# HC32F4A8 register map
File version: 1.0
CPU: CM4 r0p1, little endian, MPU, FPU, 4 interrupt priority bits
Registers are 32-bit, read-write, reset 0x0 unless marked. A register's access mark holds for its fields unless they carry their own. Offsets are from the block's base; [hi:lo] are bit positions; {n}, {i} and the like mark numbered series.

## MPU
Base 0x40050000; alternate view of ETH
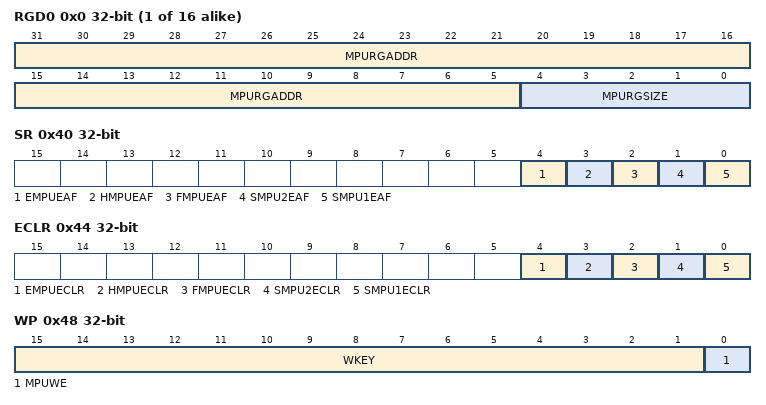
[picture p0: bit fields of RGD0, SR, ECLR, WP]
{0x0+4i} RGD{i} (i=0..15)
  [31:5] MPURGADDR, [4:0] MPURGSIZE
0x40 SR ro
  [4] EMPUEAF, [3] HMPUEAF, [2] FMPUEAF, [1] SMPU2EAF, [0] SMPU1EAF
0x44 ECLR wo
  [4] EMPUECLR, [3] HMPUECLR, [2] FMPUECLR, [1] SMPU2ECLR, [0] SMPU1ECLR
0x48 WP
  [15:1] WKEY, [0] MPUWE
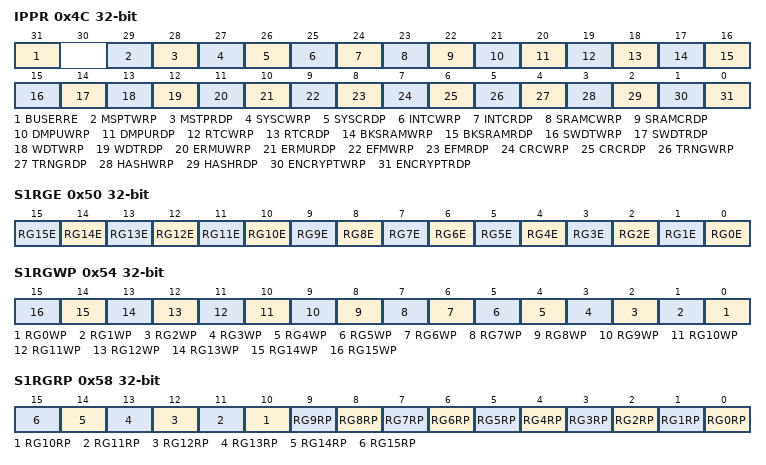
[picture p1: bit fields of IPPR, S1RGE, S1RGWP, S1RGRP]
0x4C IPPR
  [31] BUSERRE, [29] MSPTWRP, [28] MSTPRDP, [27] SYSCWRP, [26] SYSCRDP, [25] INTCWRP, [24] INTCRDP, [23] SRAMCWRP, [22] SRAMCRDP, [21] DMPUWRP, [20] DMPURDP, [19] RTCWRP, [18] RTCRDP, [17] BKSRAMWRP, [16] BKSRAMRDP, [15] SWDTWRP, [14] SWDTRDP, [13] WDTWRP, [12] WDTRDP, [11] ERMUWRP, [10] ERMURDP, [9] EFMWRP, [8] EFMRDP, [7] CRCWRP, [6] CRCRDP, [5] TRNGWRP, [4] TRNGRDP, [3] HASHWRP, [2] HASHRDP, [1] ENCRYPTWRP, [0] ENCRYPTRDP
0x50 S1RGE
  [n] RG{n}E (n=0..15)
0x54 S1RGWP
  [n] RG{n}WP (n=0..15)
0x58 S1RGRP
  [n] RG{n}RP (n=0..15)
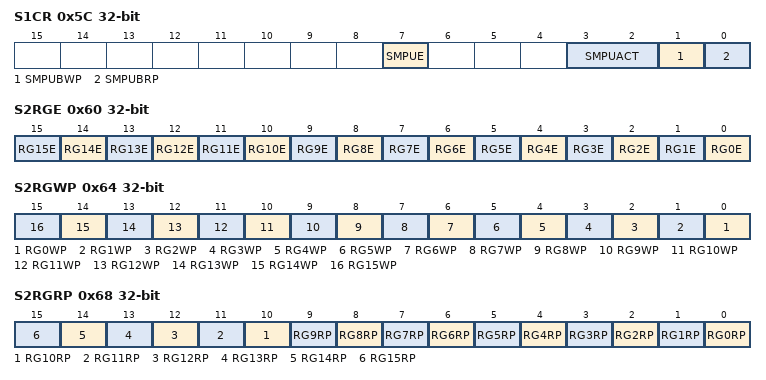
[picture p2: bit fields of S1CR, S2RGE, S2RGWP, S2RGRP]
0x5C S1CR
  [7] SMPUE, [3:2] SMPUACT, [1] SMPUBWP, [0] SMPUBRP
0x60 S2RGE
  [n] RG{n}E (n=0..15)
0x64 S2RGWP
  [n] RG{n}WP (n=0..15)
0x68 S2RGRP
  [n] RG{n}RP (n=0..15)
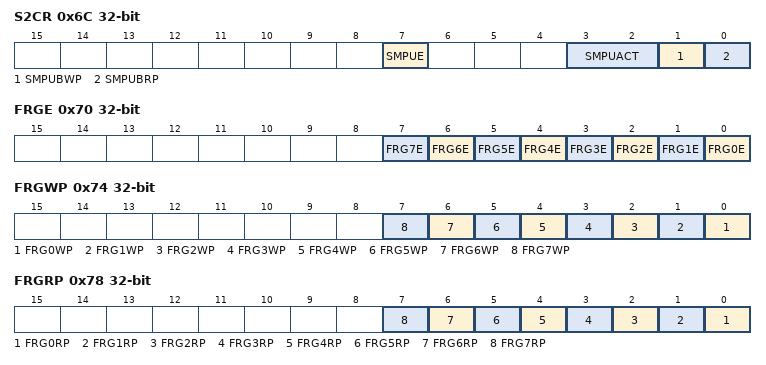
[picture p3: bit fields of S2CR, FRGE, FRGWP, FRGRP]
0x6C S2CR
  [7] SMPUE, [3:2] SMPUACT, [1] SMPUBWP, [0] SMPUBRP
0x70 FRGE
  [n] FRG{n}E (n=0..7)
0x74 FRGWP
  [n] FRG{n}WP (n=0..7)
0x78 FRGRP
  [n] FRG{n}RP (n=0..7)
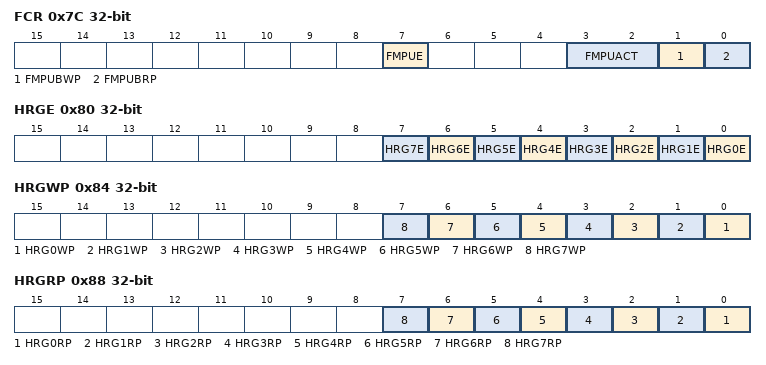
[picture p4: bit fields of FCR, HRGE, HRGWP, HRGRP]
0x7C FCR
  [7] FMPUE, [3:2] FMPUACT, [1] FMPUBWP, [0] FMPUBRP
0x80 HRGE
  [n] HRG{n}E (n=0..7)
0x84 HRGWP
  [n] HRG{n}WP (n=0..7)
0x88 HRGRP
  [n] HRG{n}RP (n=0..7)
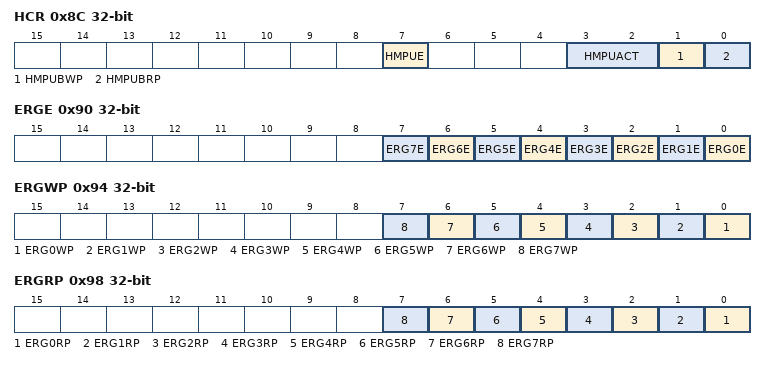
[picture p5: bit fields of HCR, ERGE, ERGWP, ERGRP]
0x8C HCR
  [7] HMPUE, [3:2] HMPUACT, [1] HMPUBWP, [0] HMPUBRP
0x90 ERGE
  [n] ERG{n}E (n=0..7)
0x94 ERGWP
  [n] ERG{n}WP (n=0..7)
0x98 ERGRP
  [n] ERG{n}RP (n=0..7)
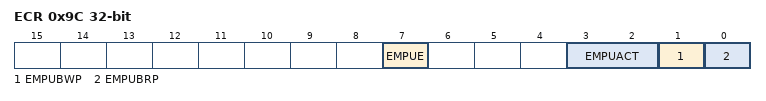
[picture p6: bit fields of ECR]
0x9C ECR
  [7] EMPUE, [3:2] EMPUACT, [1] EMPUBWP, [0] EMPUBRP

## NFC
Base 0x88100000
0x00 DATR_BASE
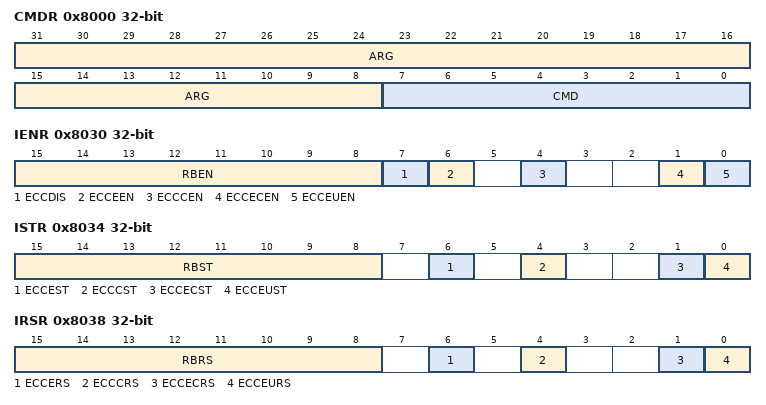
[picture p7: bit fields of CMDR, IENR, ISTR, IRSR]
0x8000 CMDR
  [31:8] ARG, [7:0] CMD
0x8004 IDXR0
0x8030 IENR
  [15:8] RBEN, [7] ECCDIS, [6] ECCEEN, [4] ECCCEN, [1] ECCECEN, [0] ECCEUEN
0x8034 ISTR
  [15:8] RBST, [6] ECCEST, [4] ECCCST, [1] ECCECST, [0] ECCEUST
0x8038 IRSR
  [15:8] RBRS, [6] ECCERS, [4] ECCCRS, [1] ECCECRS, [0] ECCEURS
0x8048 IDXR1
  [7:0] IDX1
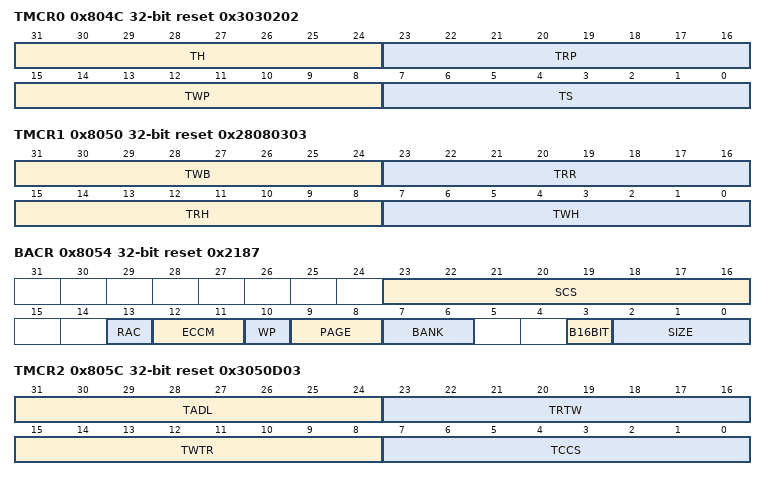
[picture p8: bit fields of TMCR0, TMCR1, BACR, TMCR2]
0x804C TMCR0 reset 0x3030202
  [31:24] TH, [23:16] TRP, [15:8] TWP, [7:0] TS
0x8050 TMCR1 reset 0x28080303
  [31:24] TWB, [23:16] TRR, [15:8] TRH, [7:0] TWH
0x8054 BACR reset 0x2187
  [23:16] SCS, [13] RAC, [12:11] ECCM, [10] WP, [9:8] PAGE, [7:6] BANK, [3] B16BIT, [2:0] SIZE
0x805C TMCR2 reset 0x3050D03
  [31:24] TADL, [23:16] TRTW, [15:8] TWTR, [7:0] TCCS
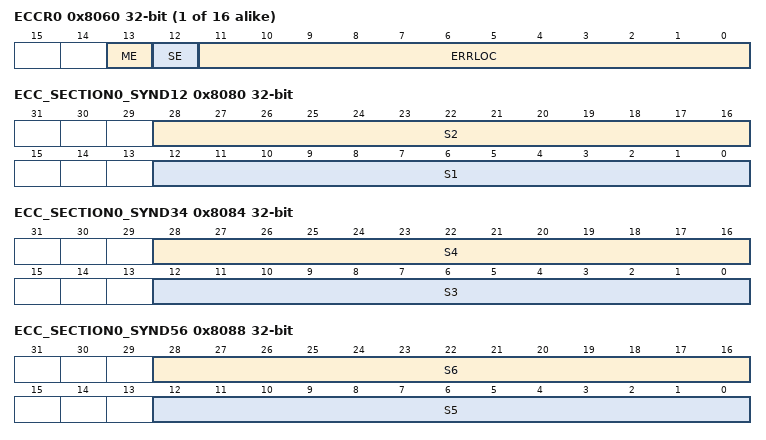
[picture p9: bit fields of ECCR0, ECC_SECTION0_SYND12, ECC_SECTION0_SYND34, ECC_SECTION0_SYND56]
{0x8060+4i} ECCR{i} ro (i=0..15)
  [13] ME, [12] SE, [11:0] ERRLOC
0x807C ECC_STAT ro (alternate view of ECCR7)
  [15:0] ERRSEC
0x8080 ECC_SECTION0_SYND12 ro (alternate view of ECCR8)
  [28:16] S2, [12:0] S1
0x8084 ECC_SECTION0_SYND34 ro (alternate view of ECCR9)
  [28:16] S4, [12:0] S3
0x8088 ECC_SECTION0_SYND56 ro (alternate view of ECCR10)
  [28:16] S6, [12:0] S5
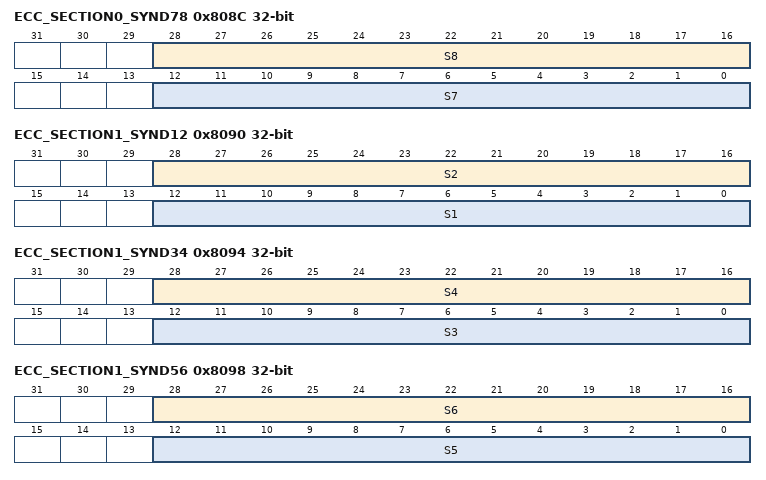
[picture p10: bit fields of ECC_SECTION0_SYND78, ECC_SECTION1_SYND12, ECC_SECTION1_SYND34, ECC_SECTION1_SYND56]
0x808C ECC_SECTION0_SYND78 ro (alternate view of ECCR11)
  [28:16] S8, [12:0] S7
0x8090 ECC_SECTION1_SYND12 ro (alternate view of ECCR12)
  [28:16] S2, [12:0] S1
0x8094 ECC_SECTION1_SYND34 ro (alternate view of ECCR13)
  [28:16] S4, [12:0] S3
0x8098 ECC_SECTION1_SYND56 ro (alternate view of ECCR14)
  [28:16] S6, [12:0] S5
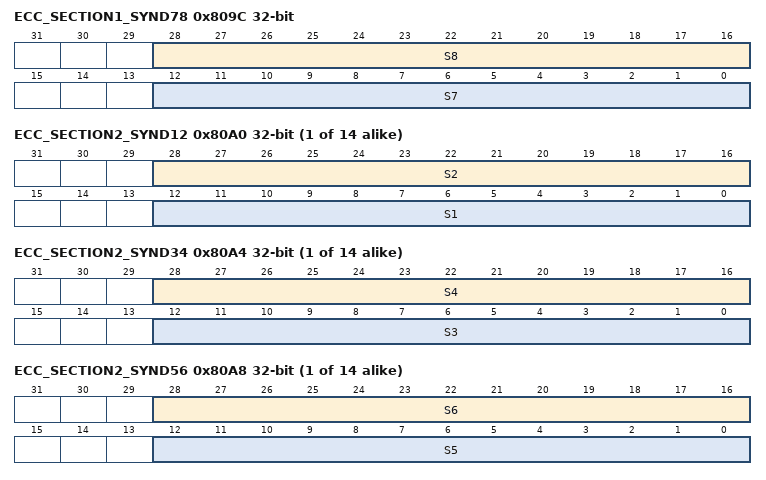
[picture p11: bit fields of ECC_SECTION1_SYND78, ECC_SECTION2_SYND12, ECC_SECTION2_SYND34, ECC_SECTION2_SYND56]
0x809C ECC_SECTION1_SYND78 ro (alternate view of ECCR15)
  [28:16] S8, [12:0] S7
{0x8080+0x10*i} ECC_SECTION{i}_SYND12 ro (i=2..15)
  [28:16] S2, [12:0] S1
{0x8084+0x10*i} ECC_SECTION{i}_SYND34 ro (i=2..15)
  [28:16] S4, [12:0] S3
{0x8088+0x10*i} ECC_SECTION{i}_SYND56 ro (i=2..15)
  [28:16] S6, [12:0] S5
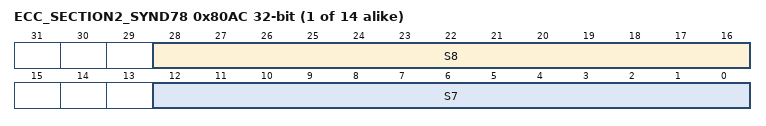
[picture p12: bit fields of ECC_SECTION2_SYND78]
{0x808C+0x10*i} ECC_SECTION{i}_SYND78 ro (i=2..15)
  [28:16] S8, [12:0] S7

## OTS
Base 0x40010600
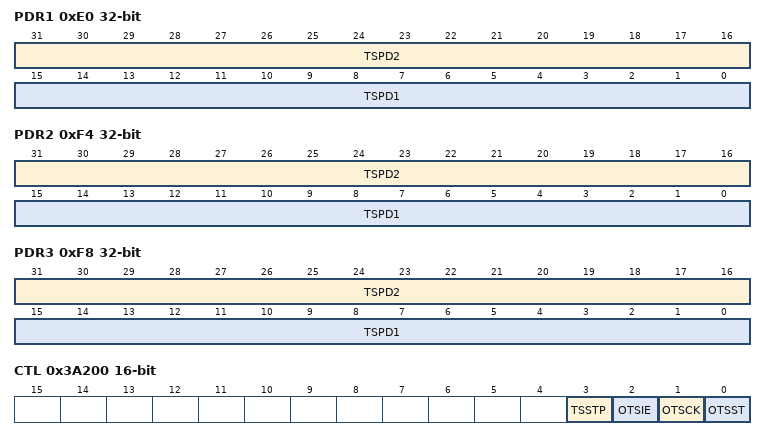
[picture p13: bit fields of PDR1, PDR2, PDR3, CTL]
0xE0 PDR1
  [31:16] TSPD2, [15:0] TSPD1
0xF4 PDR2
  [31:16] TSPD2, [15:0] TSPD1
0xF8 PDR3
  [31:16] TSPD2, [15:0] TSPD1
0x3A200 CTL 16-bit
  [3] TSSTP, [2] OTSIE, [1] OTSCK, [0] OTSST
0x3A202 DR1 16-bit
0x3A204 DR2 16-bit
0x3A206 ECR 16-bit
